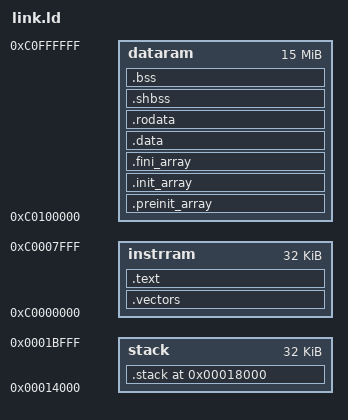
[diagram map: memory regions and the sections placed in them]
/*
 * Copyright (C) 2018-2019 ETH Zurich and University of Bologna
 *
 * Licensed under the Apache License, Version 2.0 (the "License");
 * you may not use this file except in compliance with the License.
 * You may obtain a copy of the License at
 *
 *     http://www.apache.org/licenses/LICENSE-2.0
 *
 * Unless required by applicable law or agreed to in writing, software
 * distributed under the License is distributed on an "AS IS" BASIS,
 * WITHOUT WARRANTIES OR CONDITIONS OF ANY KIND, either express or implied.
 * See the License for the specific language governing permissions and
 * limitations under the License.
 * SPDX-License-Identifier: Apache-2.0
 */

SEARCH_DIR(.)
__DYNAMIC  =  0;

MEMORY
{
    instrram    : ORIGIN = 0xc0000000, LENGTH = 0x8000
    dataram     : ORIGIN = 0xc0100000, LENGTH = 0xF00000
    stack       : ORIGIN = 0x00014000, LENGTH = 0x8000 /* 32KB */
}

/* Stack information variables */
_stack_slice_size = 0x800; /* 2KB per hart */
_stack_max_cores  = 16;
_stack_hart_count = 8;
ASSERT(_stack_hart_count > 0, "PULP core count must be at least 1");
ASSERT(_stack_hart_count <= _stack_max_cores, "PULP core count must be <= 16");
_min_stack     = _stack_slice_size * _stack_hart_count;
_stack_len     = LENGTH(stack);
_stack_start   = ORIGIN(stack) + LENGTH(stack);
ASSERT(_min_stack <= _stack_len, "Configured PULP stacks exceed stack memory");

/* We have to align each sector to word boundaries as our current s19->slm
 * conversion scripts are not able to handle non-word aligned sections. */

PHDRS
{
    text PT_LOAD;
    data PT_LOAD;
}

SECTIONS
{
    .vectors :
    {
        . = ALIGN(4);
        KEEP(*(.vectors))
    } > instrram :text

    .text : {
        . = ALIGN(4);
        _stext = .;
        *(.text)
        _etext  =  .;
        __CTOR_LIST__ = .;
        LONG((__CTOR_END__ - __CTOR_LIST__) / 4 - 2)
        *(.ctors)
        LONG(0)
        __CTOR_END__ = .;
        __DTOR_LIST__ = .;
        LONG((__DTOR_END__ - __DTOR_LIST__) / 4 - 2)
        *(.dtors)
        LONG(0)
        __DTOR_END__ = .;
        *(.lit)
        *(.shdata)
        _endtext = .;
    }  > instrram :text

    /*--------------------------------------------------------------------*/
    /* Global constructor/destructor segment                              */
    /*--------------------------------------------------------------------*/

    .preinit_array     :
    {
      PROVIDE_HIDDEN (__preinit_array_start = .);
      KEEP (*(.preinit_array))
      PROVIDE_HIDDEN (__preinit_array_end = .);
    } > dataram :data

    .init_array     :
    {
      PROVIDE_HIDDEN (__init_array_start = .);
      KEEP (*(SORT(.init_array.*)))
      KEEP (*(.init_array ))
      PROVIDE_HIDDEN (__init_array_end = .);
    } > dataram :data

    .fini_array     :
    {
      PROVIDE_HIDDEN (__fini_array_start = .);
      KEEP (*(SORT(.fini_array.*)))
      KEEP (*(.fini_array ))
      PROVIDE_HIDDEN (__fini_array_end = .);
    } > dataram :data

    .data : {
        . = ALIGN(4);
        sdata  =  .;
        _sdata  =  .;
        *(.data);
        *(.data.*)
        edata  =  .;
        _edata  =  .;
    } > dataram :data

    .rodata : {
        . = ALIGN(4);
        *(.rodata);
        *(.rodata.*)
    } > dataram :data

    .shbss :
    {
        . = ALIGN(4);
        *(.shbss)
    } > dataram :data

    .bss :
    {
        . = ALIGN(4);
        _bss_start = .;
        *(.bss)
        *(.bss.*)
        *(.sbss)
        *(.sbss.*)
        *(COMMON)
        _bss_end = .;
    } > dataram :data

    /* ensure there is enough room for stack */
    .stack ORIGIN(stack) + LENGTH(stack) - _min_stack (NOLOAD): {
        . = ALIGN(4);
        _stack_bottom = .;
        . = . + _min_stack ;
        . = ALIGN(4);
        stack = . ;
        _stack = . ;
    } > stack :NONE

}
